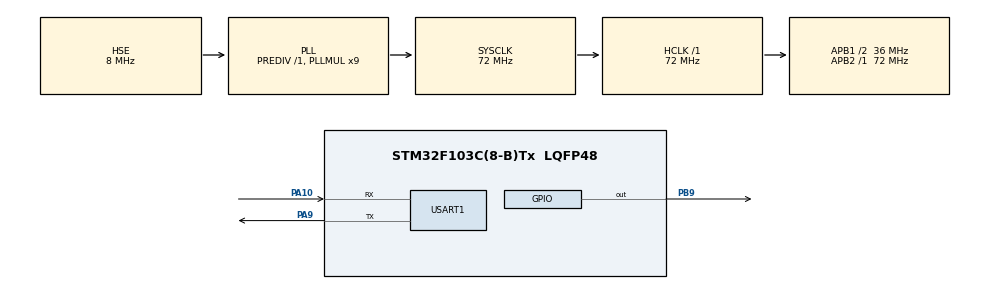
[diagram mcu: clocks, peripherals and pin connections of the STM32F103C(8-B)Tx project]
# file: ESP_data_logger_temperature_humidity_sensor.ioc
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Mcu.Family=STM32F1
Mcu.Name=STM32F103C(8-B)Tx
Mcu.Package=LQFP48
NVIC.PriorityGroup=NVIC_PRIORITYGROUP_4
NVIC.USART1_IRQn=true\:0\:0\:false\:false\:true\:true\:true\:true
PA10.Mode=Asynchronous
PA10.Signal=USART1_RX
PA13.Mode=Serial_Wire
PA13.Signal=SYS_JTMS-SWDIO
PA14.Mode=Serial_Wire
PA14.Signal=SYS_JTCK-SWCLK
PA9.Mode=Asynchronous
PA9.Signal=USART1_TX
PB9.Signal=GPIO_Output
PD0-OSC_IN.Mode=HSE-External-Oscillator
PD0-OSC_IN.Signal=RCC_OSC_IN
PD1-OSC_OUT.Mode=HSE-External-Oscillator
PD1-OSC_OUT.Signal=RCC_OSC_OUT
ProjectManager.HeapSize=0x200
ProjectManager.StackSize=0x400
ProjectManager.TargetToolchain=STM32CubeIDE
RCC.AHBFreq_Value=72000000
RCC.APB1CLKDivider=RCC_HCLK_DIV2
RCC.APB1Freq_Value=36000000
RCC.APB1TimFreq_Value=72000000
RCC.APB2Freq_Value=72000000
RCC.APB2TimFreq_Value=72000000
RCC.HCLKFreq_Value=72000000
RCC.PLLMUL=RCC_PLL_MUL9
RCC.PLLSourceVirtual=RCC_PLLSOURCE_HSE
RCC.SYSCLKFreq_VALUE=72000000
RCC.SYSCLKSource=RCC_SYSCLKSOURCE_PLLCLK
RCC.USBFreq_Value=72000000
TIM1.Prescaler=71
USART1.VirtualMode=VM_ASYNC
VP_TIM1_VS_ClockSourceINT.Mode=Internal
board=custom

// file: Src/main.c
/* USER CODE BEGIN Header */
/**
  ******************************************************************************
  * @file           : main.c
  * @brief          : Main program body
  ******************************************************************************
  * @attention
  *
  * Copyright (c) 2026 STMicroelectronics.
  * All rights reserved.
  *
  * This software is licensed under terms that can be found in the LICENSE file
  * in the root directory of this software component.
  * If no LICENSE file comes with this software, it is provided AS-IS.
  *
  ******************************************************************************
  */
/* USER CODE END Header */
#include "main.h"

/* USER CODE BEGIN Includes */

#include <stdio.h>
#include "ESPDataLogger.h"

/* USER CODE END Includes */

TIM_HandleTypeDef htim1;

UART_HandleTypeDef huart1;

void SystemClock_Config(void);
static void MX_GPIO_Init(void);
static void MX_USART1_UART_Init(void);
static void MX_TIM1_Init(void);

/* USER CODE BEGIN 0 */

//uint16_t Humidity = 0;
//uint16_t Temperature = 0;
//
//uint16_t Value_Buf[2];

float Humidity = 0;
float Temperature = 0;

float Value_Buf[2];

#define DHT22_PORT GPIOB
#define DHT22_PIN GPIO_PIN_9
uint8_t RH1, RH2, TC1, TC2, SUM, CHECK;
uint32_t pMillis, cMillis;
float tCelsius = 0;
float tFahrenheit = 0;
float RH = 0;
uint8_t RHI, RHD, TCI, TCD, TFI, TFD;
char strCopy[15];

void microDelay (uint16_t delay)
{
  __HAL_TIM_SET_COUNTER(&htim1, 0);
  while (__HAL_TIM_GET_COUNTER(&htim1) < delay);
}

uint8_t DHT22_Start (void)
{
  uint8_t Response = 0;
  GPIO_InitTypeDef GPIO_InitStructPrivate = {0};
  GPIO_InitStructPrivate.Pin = DHT22_PIN;
  GPIO_InitStructPrivate.Mode = GPIO_MODE_OUTPUT_PP;
  GPIO_InitStructPrivate.Speed = GPIO_SPEED_FREQ_LOW;
  GPIO_InitStructPrivate.Pull = GPIO_NOPULL; // 因為已設定 push pull, 所以這邊不用再設上下拉，影響不大
  HAL_GPIO_Init(DHT22_PORT, &GPIO_InitStructPrivate); // set the pin as output
  HAL_GPIO_WritePin (DHT22_PORT, DHT22_PIN, 0);   // pull the pin low
  microDelay (1300);   // wait for 1300us
  HAL_GPIO_WritePin (DHT22_PORT, DHT22_PIN, 1);   // pull the pin high
  microDelay (30);   // wait for 30us
  GPIO_InitStructPrivate.Mode = GPIO_MODE_INPUT;
  GPIO_InitStructPrivate.Pull = GPIO_PULLUP;
  HAL_GPIO_Init(DHT22_PORT, &GPIO_InitStructPrivate); // set the pin as input
  microDelay (40);
  if (!(HAL_GPIO_ReadPin (DHT22_PORT, DHT22_PIN)))
  {
    microDelay (80);
    if ((HAL_GPIO_ReadPin (DHT22_PORT, DHT22_PIN))) Response = 1;
  }
  pMillis = HAL_GetTick();
  cMillis = HAL_GetTick();
  while ((HAL_GPIO_ReadPin (DHT22_PORT, DHT22_PIN)) && pMillis + 2 > cMillis)
  {
    cMillis = HAL_GetTick();
  }
  return Response;
}

uint8_t DHT22_Read (void)
{
  uint8_t a,b = 0;
  for (a=0;a<8;a++)
  {
    pMillis = HAL_GetTick();
    cMillis = HAL_GetTick();
    while (!(HAL_GPIO_ReadPin (DHT22_PORT, DHT22_PIN)) && pMillis + 2 > cMillis)
    {  // wait for the pin to go high
      cMillis = HAL_GetTick();
    }
    microDelay (40);   // wait for 40 us to recognize '0' or '1', since  bit means '0', high time last 22-30 us. But bit means '1', high time last 68-75 us
    if (!(HAL_GPIO_ReadPin (DHT22_PORT, DHT22_PIN)))   // if the pin is low, it means this bit is '0'
      b&= ~(1<<(7-a));
    else
      b|= (1<<(7-a));
    pMillis = HAL_GetTick();
    cMillis = HAL_GetTick();
    while ((HAL_GPIO_ReadPin (DHT22_PORT, DHT22_PIN)) && pMillis + 2 > cMillis)
    {  // wait for the pin to go low, it means this bit end
      cMillis = HAL_GetTick();
    }
  }
  return b;
}

void read_sensor_and_send(void)
{
	if(DHT22_Start())
		  	      {
		  	        RH1 = DHT22_Read(); // First 8bits of humidity
		  	        RH2 = DHT22_Read(); // Second 8bits of Relative humidity
		  	        TC1 = DHT22_Read(); // First 8bits of Celsius
		  	        TC2 = DHT22_Read(); // Second 8bits of Celsius
		  	        SUM = DHT22_Read(); // Check sum
		  	        CHECK = RH1 + RH2 + TC1 + TC2;
		  	        if (CHECK == SUM)
		  	        {
		  	          if (TC1>127) // If TC1=10000000, negative temperature
		  	          {
		  	            tCelsius = (float)TC2/10*(-1);
		  	          }
		  	          else
		  	          {
		  	            tCelsius = (float)((TC1<<8)|TC2)/10;
		  	          }
		  	          tFahrenheit = tCelsius * 9/5 + 32;
		  	          RH = (float) ((RH1<<8)|RH2)/10;
		  	          RHI = RH;  // Relative humidity integral
		  	          RHD = RH*10-RHI*10; // Relative humidity decimal
		  	          sprintf(strCopy,"%d.%d %%  ", RHI, RHD);

		  	          if (tCelsius < 0)
		  	          {
		  	            TCI = tCelsius *(-1);  // Celsius integral
		  	            TCD = tCelsius*(-10)-TCI*10; // Celsius decimal
		  	            sprintf(strCopy,"-%d.%d C   ", TCI, TCD);
		  	          }
		  	          else
		  	          {
		  	            TCI = tCelsius;  // Celsius integral
		  	            TCD = tCelsius*10-TCI*10; // Celsius decimal
		  	            sprintf(strCopy,"%d.%d C   ", TCI, TCD);
		  	          }

		  	          if(tFahrenheit < 0)
		  	          {
		  	            TFI = tFahrenheit*(-1);  // Fahrenheit integral
		  	            TFD = tFahrenheit*(-10)-TFI*10; // Fahrenheit decimal
		  	            sprintf(strCopy,"-%d.%d F   ", TFI, TFD);
		  	          }
		  	          else
		  	          {
		  	            TFI = tFahrenheit;  // Fahrenheit integral
		  	            TFD = tFahrenheit*10-TFI*10; // Fahrenheit decimal
		  	            sprintf(strCopy,"%d.%d F   ", TFI, TFD);
		  	          }

		  	        }
		  	      }

	//	  Humidity = (uint16_t) RH;
		  Humidity = RH;

	//	  Temperature = (uint16_t) tCelsius;
		  Temperature = tCelsius;
	    /* USER CODE END WHILE */

	    /* USER CODE BEGIN 3 */
	//	  Value_Buf[0] =  Humidity;   // for int
	//	  Value_Buf[1] =  Temperature;  // for int

		  Value_Buf[0] = ((int)(Humidity * 10 + 0.5)) / 10.0;
		  Value_Buf[1] = ((int)(Temperature * 10 + 0.5)) / 10.0;

		  ESP_Send_Multi("KHNF01ZVGT9EEOZW", 2, Value_Buf);
}

/* USER CODE END 0 */

int main(void)
{

  /* MCU Configuration--------------------------------------------------------*/

  /* Reset of all peripherals, Initializes the Flash interface and the Systick. */
  HAL_Init();

  /* Configure the system clock */
  SystemClock_Config();

  /* Initialize all configured peripherals */
  MX_GPIO_Init();
  MX_USART1_UART_Init();
  MX_TIM1_Init();
  /* USER CODE BEGIN 2 */
  HAL_TIM_Base_Start(&htim1);

  ESP_Init("shieh-2F", "0492393511");

  uint32_t lastTime = HAL_GetTick();

  /* USER CODE END 2 */

  /* Infinite loop */
  /* USER CODE BEGIN WHILE */
  while (1)

  {
	  if(HAL_GetTick() - lastTime >= 30000)
	          {
	              lastTime = HAL_GetTick();
	              read_sensor_and_send();
	          }

  }
  /* USER CODE END 3 */
}

void SystemClock_Config(void)
{
  RCC_OscInitTypeDef RCC_OscInitStruct = {0};
  RCC_ClkInitTypeDef RCC_ClkInitStruct = {0};

  /** Initializes the RCC Oscillators according to the specified parameters
  * in the RCC_OscInitTypeDef structure.
  */
  RCC_OscInitStruct.OscillatorType = RCC_OSCILLATORTYPE_HSE;
  RCC_OscInitStruct.HSEState = RCC_HSE_ON;
  RCC_OscInitStruct.HSEPredivValue = RCC_HSE_PREDIV_DIV1;
  RCC_OscInitStruct.HSIState = RCC_HSI_ON;
  RCC_OscInitStruct.PLL.PLLState = RCC_PLL_ON;
  RCC_OscInitStruct.PLL.PLLSource = RCC_PLLSOURCE_HSE;
  RCC_OscInitStruct.PLL.PLLMUL = RCC_PLL_MUL9;
  if (HAL_RCC_OscConfig(&RCC_OscInitStruct) != HAL_OK)
  {
    Error_Handler();
  }

  /** Initializes the CPU, AHB and APB buses clocks
  */
  RCC_ClkInitStruct.ClockType = RCC_CLOCKTYPE_HCLK|RCC_CLOCKTYPE_SYSCLK
                              |RCC_CLOCKTYPE_PCLK1|RCC_CLOCKTYPE_PCLK2;
  RCC_ClkInitStruct.SYSCLKSource = RCC_SYSCLKSOURCE_PLLCLK;
  RCC_ClkInitStruct.AHBCLKDivider = RCC_SYSCLK_DIV1;
  RCC_ClkInitStruct.APB1CLKDivider = RCC_HCLK_DIV2;
  RCC_ClkInitStruct.APB2CLKDivider = RCC_HCLK_DIV1;

  if (HAL_RCC_ClockConfig(&RCC_ClkInitStruct, FLASH_LATENCY_2) != HAL_OK)
  {
    Error_Handler();
  }
}

static void MX_TIM1_Init(void)
{

  TIM_ClockConfigTypeDef sClockSourceConfig = {0};
  TIM_MasterConfigTypeDef sMasterConfig = {0};

  htim1.Instance = TIM1;
  htim1.Init.Prescaler = 71;
  htim1.Init.CounterMode = TIM_COUNTERMODE_UP;
  htim1.Init.Period = 65535;
  htim1.Init.ClockDivision = TIM_CLOCKDIVISION_DIV1;
  htim1.Init.RepetitionCounter = 0;
  htim1.Init.AutoReloadPreload = TIM_AUTORELOAD_PRELOAD_DISABLE;
  if (HAL_TIM_Base_Init(&htim1) != HAL_OK)
  {
    Error_Handler();
  }
  sClockSourceConfig.ClockSource = TIM_CLOCKSOURCE_INTERNAL;
  if (HAL_TIM_ConfigClockSource(&htim1, &sClockSourceConfig) != HAL_OK)
  {
    Error_Handler();
  }
  sMasterConfig.MasterOutputTrigger = TIM_TRGO_RESET;
  sMasterConfig.MasterSlaveMode = TIM_MASTERSLAVEMODE_DISABLE;
  if (HAL_TIMEx_MasterConfigSynchronization(&htim1, &sMasterConfig) != HAL_OK)
  {
    Error_Handler();
  }

}

static void MX_USART1_UART_Init(void)
{

  huart1.Instance = USART1;
  huart1.Init.BaudRate = 115200;
  huart1.Init.WordLength = UART_WORDLENGTH_8B;
  huart1.Init.StopBits = UART_STOPBITS_1;
  huart1.Init.Parity = UART_PARITY_NONE;
  huart1.Init.Mode = UART_MODE_TX_RX;
  huart1.Init.HwFlowCtl = UART_HWCONTROL_NONE;
  huart1.Init.OverSampling = UART_OVERSAMPLING_16;
  if (HAL_UART_Init(&huart1) != HAL_OK)
  {
    Error_Handler();
  }

}

static void MX_GPIO_Init(void)
{
  GPIO_InitTypeDef GPIO_InitStruct = {0};

  /* GPIO Ports Clock Enable */
  __HAL_RCC_GPIOD_CLK_ENABLE();
  __HAL_RCC_GPIOA_CLK_ENABLE();
  __HAL_RCC_GPIOB_CLK_ENABLE();

  /*Configure GPIO pin Output Level */
  HAL_GPIO_WritePin(GPIOB, GPIO_PIN_9, GPIO_PIN_RESET);

  /*Configure GPIO pin : PB9 */
  GPIO_InitStruct.Pin = GPIO_PIN_9;
  GPIO_InitStruct.Mode = GPIO_MODE_OUTPUT_PP;
  GPIO_InitStruct.Pull = GPIO_NOPULL;
  GPIO_InitStruct.Speed = GPIO_SPEED_FREQ_LOW;
  HAL_GPIO_Init(GPIOB, &GPIO_InitStruct);

}

void Error_Handler(void)
{
  __disable_irq();
  while (1)
  {
  }
}
